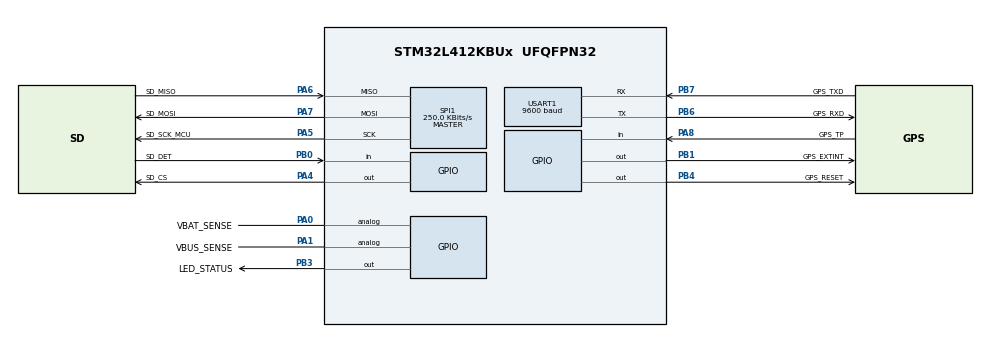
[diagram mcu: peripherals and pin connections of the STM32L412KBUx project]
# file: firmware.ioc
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Mcu.Family=STM32L4
Mcu.Name=STM32L412KBUx
Mcu.Package=UFQFPN32
NVIC.PriorityGroup=NVIC_PRIORITYGROUP_4
PA0-CK_IN.GPIO_Label=VBAT_SENSE
PA0-CK_IN.Signal=GPIO_Analog
PA1.GPIO_Label=VBUS_SENSE
PA1.Signal=GPIO_Analog
PA13\ (JTMS/SWDIO).Mode=Serial_Wire
PA13\ (JTMS/SWDIO).Signal=SYS_JTMS-SWDIO
PA14\ (JTCK/SWCLK).Mode=Serial_Wire
PA14\ (JTCK/SWCLK).Signal=SYS_JTCK-SWCLK
PA4.GPIO_Label=SD_CS
PA4.GPIO_Speed=GPIO_SPEED_FREQ_HIGH
PA4.PinState=GPIO_PIN_SET
PA4.Signal=GPIO_Output
PA5.GPIO_Label=SD_SCK_MCU
PA5.Mode=Full_Duplex_Master
PA5.Signal=SPI1_SCK
PA6.GPIO_Label=SD_MISO
PA6.Mode=Full_Duplex_Master
PA6.Signal=SPI1_MISO
PA7.GPIO_Label=SD_MOSI
PA7.Mode=Full_Duplex_Master
PA7.Signal=SPI1_MOSI
PA8.GPIO_Label=GPS_TP
PA8.Signal=GPIO_Input
PB0.GPIO_Label=SD_DET
PB0.Signal=GPIO_Input
PB1.GPIO_Label=GPS_EXTINT
PB1.Signal=GPIO_Output
PB3\ (JTDO/TRACESWO).GPIO_Label=LED_STATUS
PB3\ (JTDO/TRACESWO).Signal=GPIO_Output
PB4\ (NJTRST).GPIO_Label=GPS_RESET
PB4\ (NJTRST).GPIO_ModeDefaultOutputPP=GPIO_MODE_OUTPUT_OD
PB4\ (NJTRST).PinState=GPIO_PIN_SET
PB4\ (NJTRST).Signal=GPIO_Output
PB6.GPIO_Label=GPS_RXD
PB6.Mode=Asynchronous
PB6.Signal=USART1_TX
PB7.GPIO_Label=GPS_TXD
PB7.Mode=Asynchronous
PB7.Signal=USART1_RX
ProjectManager.HeapSize=0x200
ProjectManager.StackSize=0x400
ProjectManager.TargetToolchain=CMake
RCC.ADCFreq_Value=16000000
RCC.AHBFreq_Value=16000000
RCC.APB1Freq_Value=16000000
RCC.APB1TimFreq_Value=16000000
RCC.APB2Freq_Value=16000000
RCC.APB2TimFreq_Value=16000000
RCC.CortexFreq_Value=16000000
RCC.HCLKFreq_Value=16000000
RCC.HSE_VALUE=8000000
RCC.HSI48_VALUE=48000000
RCC.HSI_VALUE=16000000
RCC.LSE_VALUE=32768
RCC.MSI_VALUE=4000000
RCC.SYSCLKFreq_VALUE=16000000
RCC.SYSCLKSource=RCC_SYSCLKSOURCE_HSI
RCC.USBFreq_Value=4000000
RCC.VCOOutputFreq_Value=32000000
SPI1.BaudRatePrescaler=SPI_BAUDRATEPRESCALER_64
SPI1.CalculateBaudRate=250.0 KBits/s
SPI1.DataSize=SPI_DATASIZE_8BIT
SPI1.Direction=SPI_DIRECTION_2LINES
SPI1.Mode=SPI_MODE_MASTER
SPI1.VirtualType=VM_MASTER
USART1.BaudRate=9600
USART1.VirtualMode-Asynchronous=VM_ASYNC
board=custom

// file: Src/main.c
/* USER CODE BEGIN Header */
/**
  ******************************************************************************
  * @file           : main.c
  * @brief          : Main program body
  ******************************************************************************
  * @attention
  *
  * Copyright (c) 2026 STMicroelectronics.
  * All rights reserved.
  *
  * This software is licensed under terms that can be found in the LICENSE file
  * in the root directory of this software component.
  * If no LICENSE file comes with this software, it is provided AS-IS.
  *
  ******************************************************************************
  */
/* USER CODE END Header */
#include "main.h"

/* USER CODE BEGIN Includes */
#include "app.h"

/* USER CODE END Includes */

void SystemClock_Config(void);
static void MX_GPIO_Init(void);
static void MX_SPI1_Init(void);
static void MX_USART1_UART_Init(void);

int main(void)
{

  /* MCU Configuration--------------------------------------------------------*/

  /* Reset of all peripherals, Initializes the Flash interface and the Systick. */
  LL_APB2_GRP1_EnableClock(LL_APB2_GRP1_PERIPH_SYSCFG);
  LL_APB1_GRP1_EnableClock(LL_APB1_GRP1_PERIPH_PWR);

  /* System interrupt init*/
  NVIC_SetPriorityGrouping(NVIC_PRIORITYGROUP_4);

  /* SysTick_IRQn interrupt configuration */
  NVIC_SetPriority(SysTick_IRQn, NVIC_EncodePriority(NVIC_GetPriorityGrouping(),15, 0));

  /* Configure the system clock */
  SystemClock_Config();

  /* Initialize all configured peripherals */
  MX_GPIO_Init();
  MX_SPI1_Init();
  MX_USART1_UART_Init();
  /* USER CODE BEGIN 2 */
  app_run();

  /* USER CODE END 2 */

  /* Infinite loop */
  while (1)
  {

  }
}

void SystemClock_Config(void)
{
  LL_FLASH_SetLatency(LL_FLASH_LATENCY_0);
  while(LL_FLASH_GetLatency()!= LL_FLASH_LATENCY_0)
  {
  }
  LL_PWR_SetRegulVoltageScaling(LL_PWR_REGU_VOLTAGE_SCALE1);
  while (LL_PWR_IsActiveFlag_VOS() != 0)
  {
  }
  LL_RCC_HSI_Enable();

   /* Wait till HSI is ready */
  while(LL_RCC_HSI_IsReady() != 1)
  {

  }
  LL_RCC_HSI_SetCalibTrimming(64);
  LL_RCC_SetSysClkSource(LL_RCC_SYS_CLKSOURCE_HSI);

   /* Wait till System clock is ready */
  while(LL_RCC_GetSysClkSource() != LL_RCC_SYS_CLKSOURCE_STATUS_HSI)
  {

  }
  LL_RCC_SetAHBPrescaler(LL_RCC_SYSCLK_DIV_1);
  LL_RCC_SetAPB1Prescaler(LL_RCC_APB1_DIV_1);
  LL_RCC_SetAPB2Prescaler(LL_RCC_APB2_DIV_1);

  LL_Init1msTick(16000000);

  LL_SetSystemCoreClock(16000000);
}

static void MX_SPI1_Init(void)
{

  LL_SPI_InitTypeDef SPI_InitStruct = {0};

  LL_GPIO_InitTypeDef GPIO_InitStruct = {0};

  /* Peripheral clock enable */
  LL_APB2_GRP1_EnableClock(LL_APB2_GRP1_PERIPH_SPI1);

  LL_AHB2_GRP1_EnableClock(LL_AHB2_GRP1_PERIPH_GPIOA);
  /**SPI1 GPIO Configuration
  PA5   ------> SPI1_SCK
  PA6   ------> SPI1_MISO
  PA7   ------> SPI1_MOSI
  */
  GPIO_InitStruct.Pin = SD_SCK_MCU_Pin|SD_MISO_Pin|SD_MOSI_Pin;
  GPIO_InitStruct.Mode = LL_GPIO_MODE_ALTERNATE;
  GPIO_InitStruct.Speed = LL_GPIO_SPEED_FREQ_VERY_HIGH;
  GPIO_InitStruct.OutputType = LL_GPIO_OUTPUT_PUSHPULL;
  GPIO_InitStruct.Pull = LL_GPIO_PULL_NO;
  GPIO_InitStruct.Alternate = LL_GPIO_AF_5;
  LL_GPIO_Init(GPIOA, &GPIO_InitStruct);

  /* SPI1 parameter configuration*/
  SPI_InitStruct.TransferDirection = LL_SPI_FULL_DUPLEX;
  SPI_InitStruct.Mode = LL_SPI_MODE_MASTER;
  SPI_InitStruct.DataWidth = LL_SPI_DATAWIDTH_8BIT;
  SPI_InitStruct.ClockPolarity = LL_SPI_POLARITY_LOW;
  SPI_InitStruct.ClockPhase = LL_SPI_PHASE_1EDGE;
  SPI_InitStruct.NSS = LL_SPI_NSS_SOFT;
  SPI_InitStruct.BaudRate = LL_SPI_BAUDRATEPRESCALER_DIV64;
  SPI_InitStruct.BitOrder = LL_SPI_MSB_FIRST;
  SPI_InitStruct.CRCCalculation = LL_SPI_CRCCALCULATION_DISABLE;
  SPI_InitStruct.CRCPoly = 7;
  LL_SPI_Init(SPI1, &SPI_InitStruct);
  LL_SPI_SetStandard(SPI1, LL_SPI_PROTOCOL_MOTOROLA);
  LL_SPI_EnableNSSPulseMgt(SPI1);

}

static void MX_USART1_UART_Init(void)
{

  LL_USART_InitTypeDef USART_InitStruct = {0};

  LL_GPIO_InitTypeDef GPIO_InitStruct = {0};

  LL_RCC_SetUSARTClockSource(LL_RCC_USART1_CLKSOURCE_PCLK2);

  /* Peripheral clock enable */
  LL_APB2_GRP1_EnableClock(LL_APB2_GRP1_PERIPH_USART1);

  LL_AHB2_GRP1_EnableClock(LL_AHB2_GRP1_PERIPH_GPIOB);
  /**USART1 GPIO Configuration
  PB6   ------> USART1_TX
  PB7   ------> USART1_RX
  */
  GPIO_InitStruct.Pin = GPS_RXD_Pin|GPS_TXD_Pin;
  GPIO_InitStruct.Mode = LL_GPIO_MODE_ALTERNATE;
  GPIO_InitStruct.Speed = LL_GPIO_SPEED_FREQ_VERY_HIGH;
  GPIO_InitStruct.OutputType = LL_GPIO_OUTPUT_PUSHPULL;
  GPIO_InitStruct.Pull = LL_GPIO_PULL_NO;
  GPIO_InitStruct.Alternate = LL_GPIO_AF_7;
  LL_GPIO_Init(GPIOB, &GPIO_InitStruct);

  USART_InitStruct.BaudRate = 9600;
  USART_InitStruct.DataWidth = LL_USART_DATAWIDTH_8B;
  USART_InitStruct.StopBits = LL_USART_STOPBITS_1;
  USART_InitStruct.Parity = LL_USART_PARITY_NONE;
  USART_InitStruct.TransferDirection = LL_USART_DIRECTION_TX_RX;
  USART_InitStruct.HardwareFlowControl = LL_USART_HWCONTROL_NONE;
  USART_InitStruct.OverSampling = LL_USART_OVERSAMPLING_16;
  LL_USART_Init(USART1, &USART_InitStruct);
  LL_USART_ConfigAsyncMode(USART1);
  LL_USART_Enable(USART1);

}

static void MX_GPIO_Init(void)
{
  LL_GPIO_InitTypeDef GPIO_InitStruct = {0};

  /* GPIO Ports Clock Enable */
  LL_AHB2_GRP1_EnableClock(LL_AHB2_GRP1_PERIPH_GPIOC);
  LL_AHB2_GRP1_EnableClock(LL_AHB2_GRP1_PERIPH_GPIOA);
  LL_AHB2_GRP1_EnableClock(LL_AHB2_GRP1_PERIPH_GPIOB);
  LL_AHB2_GRP1_EnableClock(LL_AHB2_GRP1_PERIPH_GPIOH);

  /**/
  LL_GPIO_SetOutputPin(SD_CS_GPIO_Port, SD_CS_Pin);

  /**/
  LL_GPIO_SetOutputPin(GPS_RESET_GPIO_Port, GPS_RESET_Pin);

  /**/
  LL_GPIO_ResetOutputPin(GPIOB, GPS_EXTINT_Pin|LED_STATUS_Pin);

  /**/
  GPIO_InitStruct.Pin = LL_GPIO_PIN_14|LL_GPIO_PIN_15;
  GPIO_InitStruct.Mode = LL_GPIO_MODE_ANALOG;
  GPIO_InitStruct.Pull = LL_GPIO_PULL_NO;
  LL_GPIO_Init(GPIOC, &GPIO_InitStruct);

  /**/
  GPIO_InitStruct.Pin = VBAT_SENSE_Pin|VBUS_SENSE_Pin|LL_GPIO_PIN_2|LL_GPIO_PIN_3
                          |LL_GPIO_PIN_9|LL_GPIO_PIN_10|LL_GPIO_PIN_11|LL_GPIO_PIN_12
                          |LL_GPIO_PIN_15;
  GPIO_InitStruct.Mode = LL_GPIO_MODE_ANALOG;
  GPIO_InitStruct.Pull = LL_GPIO_PULL_NO;
  LL_GPIO_Init(GPIOA, &GPIO_InitStruct);

  /**/
  GPIO_InitStruct.Pin = SD_CS_Pin;
  GPIO_InitStruct.Mode = LL_GPIO_MODE_OUTPUT;
  GPIO_InitStruct.Speed = LL_GPIO_SPEED_FREQ_HIGH;
  GPIO_InitStruct.OutputType = LL_GPIO_OUTPUT_PUSHPULL;
  GPIO_InitStruct.Pull = LL_GPIO_PULL_NO;
  LL_GPIO_Init(SD_CS_GPIO_Port, &GPIO_InitStruct);

  /**/
  GPIO_InitStruct.Pin = SD_DET_Pin;
  GPIO_InitStruct.Mode = LL_GPIO_MODE_INPUT;
  GPIO_InitStruct.Pull = LL_GPIO_PULL_NO;
  LL_GPIO_Init(SD_DET_GPIO_Port, &GPIO_InitStruct);

  /**/
  GPIO_InitStruct.Pin = GPS_EXTINT_Pin|LED_STATUS_Pin;
  GPIO_InitStruct.Mode = LL_GPIO_MODE_OUTPUT;
  GPIO_InitStruct.Speed = LL_GPIO_SPEED_FREQ_LOW;
  GPIO_InitStruct.OutputType = LL_GPIO_OUTPUT_PUSHPULL;
  GPIO_InitStruct.Pull = LL_GPIO_PULL_NO;
  LL_GPIO_Init(GPIOB, &GPIO_InitStruct);

  /**/
  GPIO_InitStruct.Pin = GPS_TP_Pin;
  GPIO_InitStruct.Mode = LL_GPIO_MODE_INPUT;
  GPIO_InitStruct.Pull = LL_GPIO_PULL_NO;
  LL_GPIO_Init(GPS_TP_GPIO_Port, &GPIO_InitStruct);

  /**/
  GPIO_InitStruct.Pin = GPS_RESET_Pin;
  GPIO_InitStruct.Mode = LL_GPIO_MODE_OUTPUT;
  GPIO_InitStruct.Speed = LL_GPIO_SPEED_FREQ_LOW;
  GPIO_InitStruct.OutputType = LL_GPIO_OUTPUT_OPENDRAIN;
  GPIO_InitStruct.Pull = LL_GPIO_PULL_NO;
  LL_GPIO_Init(GPS_RESET_GPIO_Port, &GPIO_InitStruct);

  /**/
  GPIO_InitStruct.Pin = LL_GPIO_PIN_5;
  GPIO_InitStruct.Mode = LL_GPIO_MODE_ANALOG;
  GPIO_InitStruct.Pull = LL_GPIO_PULL_NO;
  LL_GPIO_Init(GPIOB, &GPIO_InitStruct);

  /**/
  GPIO_InitStruct.Pin = LL_GPIO_PIN_3;
  GPIO_InitStruct.Mode = LL_GPIO_MODE_ANALOG;
  GPIO_InitStruct.Pull = LL_GPIO_PULL_NO;
  LL_GPIO_Init(GPIOH, &GPIO_InitStruct);

}

void Error_Handler(void)
{
  __disable_irq();
  while (1)
  {
  }
}
